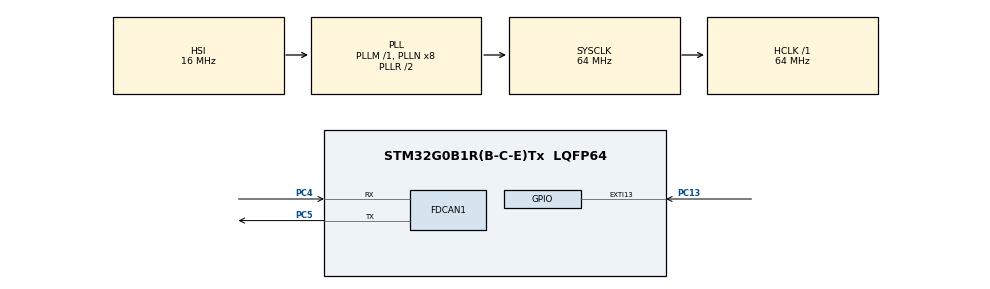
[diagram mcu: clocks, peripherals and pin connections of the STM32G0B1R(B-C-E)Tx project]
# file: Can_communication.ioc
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FDCAN1.ClockDivider=FDCAN_CLOCK_DIV1
FDCAN1.DataPrescaler=8
FDCAN1.DataTimeSeg1=13
FDCAN1.DataTimeSeg2=2
FDCAN1.NominalPrescaler=8
FDCAN1.NominalTimeSeg1=13
Mcu.Family=STM32G0
Mcu.Name=STM32G0B1R(B-C-E)Tx
Mcu.Package=LQFP64
NVIC.EXTI4_15_IRQn=true\:0\:0\:false\:false\:true\:true\:true
NVIC.TIM16_FDCAN_IT0_IRQn=true\:0\:0\:false\:false\:true\:true\:true
PA13.Mode=Serial_Wire
PA13.Signal=SYS_SWDIO
PA14-BOOT0.Mode=Serial_Wire
PA14-BOOT0.Signal=SYS_SWCLK
PC13.Signal=GPXTI13
PC4.Mode=FDCAN_Activate
PC4.Signal=FDCAN1_RX
PC5.Mode=FDCAN_Activate
PC5.Signal=FDCAN1_TX
PF0-OSC_IN\ (PF0).Mode=HSE-External-Oscillator
PF0-OSC_IN\ (PF0).Signal=RCC_OSC_IN
PF1-OSC_OUT\ (PF1).Mode=HSE-External-Oscillator
PF1-OSC_OUT\ (PF1).Signal=RCC_OSC_OUT
ProjectManager.HeapSize=0x200
ProjectManager.StackSize=0x400
ProjectManager.TargetToolchain=STM32CubeIDE
RCC.ADCFreq_Value=64000000
RCC.AHBFreq_Value=64000000
RCC.CortexFreq_Value=64000000
RCC.EXTERNAL_CLOCK_VALUE=48000
RCC.HCLKFreq_Value=64000000
RCC.HSE_VALUE=8000000
RCC.HSI48_VALUE=48000000
RCC.HSI_VALUE=16000000
RCC.LSE_VALUE=32768
RCC.SYSCLKFreq_VALUE=64000000
RCC.SYSCLKSource=RCC_SYSCLKSOURCE_PLLCLK
RCC.USBFreq_Value=48000000
RCC.VCOOutputFreq_Value=128000000
VP_SYS_VS_DBSignals.Mode=DisableDeadBatterySignals
board=custom

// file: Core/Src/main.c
/* USER CODE BEGIN Header */
/**
  ******************************************************************************
  * @file           : main.c
  * @brief          : Main program body
  ******************************************************************************
  * @attention
  *
  * Copyright (c) 2022 STMicroelectronics.
  * All rights reserved.
  *
  * This software is licensed under terms that can be found in the LICENSE file
  * in the root directory of this software component.
  * If no LICENSE file comes with this software, it is provided AS-IS.
  *
  ******************************************************************************
  */
/* USER CODE END Header */
#include "main.h"

FDCAN_HandleTypeDef hfdcan1;

void SystemClock_Config(void);
static void MX_GPIO_Init(void);
static void MX_FDCAN1_Init(void);

/* USER CODE BEGIN 0 */

FDCAN_TxHeaderTypeDef TxHeader;
FDCAN_RxHeaderTypeDef RxHeader;

uint8_t TxData[8];
uint8_t RxData[8];

uint32_t TxMailBox;
/* USER CODE END 0 */

int main(void)
{

  /* MCU Configuration--------------------------------------------------------*/

  /* Reset of all peripherals, Initializes the Flash interface and the Systick. */
  HAL_Init();

  /* Configure the system clock */
  SystemClock_Config();

  /* Initialize all configured peripherals */
  MX_GPIO_Init();
  MX_FDCAN1_Init();
  /* USER CODE BEGIN 2 */

  HAL_FDCAN_Start(&hfdcan1);

  HAL_FDCAN_ActivateNotification(&hfdcan1, , FDCAN_TX_BUFFER0);//3.parametre???

  /* USER CODE END 2 */

  /* Infinite loop */
  while (1)
  {

  }
}

void SystemClock_Config(void)
{
  RCC_OscInitTypeDef RCC_OscInitStruct = {0};
  RCC_ClkInitTypeDef RCC_ClkInitStruct = {0};

  /** Configure the main internal regulator output voltage
  */
  HAL_PWREx_ControlVoltageScaling(PWR_REGULATOR_VOLTAGE_SCALE1);
  /** Initializes the RCC Oscillators according to the specified parameters
  * in the RCC_OscInitTypeDef structure.
  */
  RCC_OscInitStruct.OscillatorType = RCC_OSCILLATORTYPE_HSI;
  RCC_OscInitStruct.HSIState = RCC_HSI_ON;
  RCC_OscInitStruct.HSIDiv = RCC_HSI_DIV1;
  RCC_OscInitStruct.HSICalibrationValue = RCC_HSICALIBRATION_DEFAULT;
  RCC_OscInitStruct.PLL.PLLState = RCC_PLL_ON;
  RCC_OscInitStruct.PLL.PLLSource = RCC_PLLSOURCE_HSI;
  RCC_OscInitStruct.PLL.PLLM = RCC_PLLM_DIV1;
  RCC_OscInitStruct.PLL.PLLN = 8;
  RCC_OscInitStruct.PLL.PLLP = RCC_PLLP_DIV2;
  RCC_OscInitStruct.PLL.PLLQ = RCC_PLLQ_DIV2;
  RCC_OscInitStruct.PLL.PLLR = RCC_PLLR_DIV2;
  if (HAL_RCC_OscConfig(&RCC_OscInitStruct) != HAL_OK)
  {
    Error_Handler();
  }
  /** Initializes the CPU, AHB and APB buses clocks
  */
  RCC_ClkInitStruct.ClockType = RCC_CLOCKTYPE_HCLK|RCC_CLOCKTYPE_SYSCLK
                              |RCC_CLOCKTYPE_PCLK1;
  RCC_ClkInitStruct.SYSCLKSource = RCC_SYSCLKSOURCE_PLLCLK;
  RCC_ClkInitStruct.AHBCLKDivider = RCC_SYSCLK_DIV1;
  RCC_ClkInitStruct.APB1CLKDivider = RCC_HCLK_DIV1;

  if (HAL_RCC_ClockConfig(&RCC_ClkInitStruct, FLASH_LATENCY_2) != HAL_OK)
  {
    Error_Handler();
  }
}

static void MX_FDCAN1_Init(void)
{

  hfdcan1.Instance = FDCAN1;
  hfdcan1.Init.ClockDivider = FDCAN_CLOCK_DIV1;
  hfdcan1.Init.FrameFormat = FDCAN_FRAME_CLASSIC;
  hfdcan1.Init.Mode = FDCAN_MODE_NORMAL;
  hfdcan1.Init.AutoRetransmission = DISABLE;
  hfdcan1.Init.TransmitPause = DISABLE;
  hfdcan1.Init.ProtocolException = DISABLE;
  hfdcan1.Init.NominalPrescaler = 8;
  hfdcan1.Init.NominalSyncJumpWidth = 1;
  hfdcan1.Init.NominalTimeSeg1 = 13;
  hfdcan1.Init.NominalTimeSeg2 = 2;
  hfdcan1.Init.DataPrescaler = 8;
  hfdcan1.Init.DataSyncJumpWidth = 1;
  hfdcan1.Init.DataTimeSeg1 = 13;
  hfdcan1.Init.DataTimeSeg2 = 2;
  hfdcan1.Init.StdFiltersNbr = 0;
  hfdcan1.Init.ExtFiltersNbr = 0;
  hfdcan1.Init.TxFifoQueueMode = FDCAN_TX_FIFO_OPERATION;
  if (HAL_FDCAN_Init(&hfdcan1) != HAL_OK)
  {
    Error_Handler();
  }

}

static void MX_GPIO_Init(void)
{
  GPIO_InitTypeDef GPIO_InitStruct = {0};

  /* GPIO Ports Clock Enable */
  __HAL_RCC_GPIOC_CLK_ENABLE();
  __HAL_RCC_GPIOF_CLK_ENABLE();
  __HAL_RCC_GPIOA_CLK_ENABLE();

  /*Configure GPIO pin : PC13 */
  GPIO_InitStruct.Pin = GPIO_PIN_13;
  GPIO_InitStruct.Mode = GPIO_MODE_IT_RISING;
  GPIO_InitStruct.Pull = GPIO_NOPULL;
  HAL_GPIO_Init(GPIOC, &GPIO_InitStruct);

  /* EXTI interrupt init*/
  HAL_NVIC_SetPriority(EXTI4_15_IRQn, 0, 0);
  HAL_NVIC_EnableIRQ(EXTI4_15_IRQn);

}

void Error_Handler(void)
{
  __disable_irq();
  while (1)
  {
  }
}
